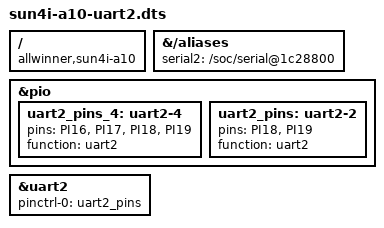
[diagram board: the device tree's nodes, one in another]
/dts-v1/;
/plugin/;

/ {
	compatible = "allwinner,sun4i-a10";

	fragment@0 {
		target-path = "/aliases";
		__overlay__ {
			serial2 = "/soc/serial@1c28800";
		};
	};

	fragment@1 {
		target = <&pio>;
		__overlay__ {
			uart2_pins_4: uart2-4 {
				pins = "PI16", "PI17", "PI18", "PI19";
				function = "uart2";
			};

			uart2_pins: uart2-2 {
				pins = "PI18", "PI19";
				function = "uart2";
			};
		};
	};

	fragment@2 {
		target = <&uart2>;
		 __overlay__ {
			pinctrl-names = "default";
			pinctrl-0 = <&uart2_pins>;
			status = "okay";
		};
	};
};
